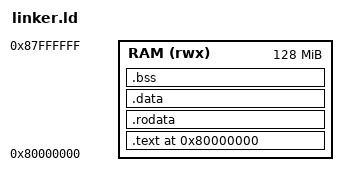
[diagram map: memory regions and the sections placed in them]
ENTRY(_start)

MEMORY
{
    RAM (rwx) : ORIGIN = 0x80000000, LENGTH = 128M
}

SECTIONS
{
    . = ORIGIN(RAM);

    .text :
    {
        *(.text.start)
        *(.text*)
    } > RAM

    .rodata :
    {
        *(.rodata*)
    } > RAM

    .data :
    {
        __data_start = .;
        *(.data*)
        __data_end = .;
    } > RAM

    .bss :
    {
        __bss_start = .;
        *(.bss*)
        *(COMMON)
        __bss_end = .;
    } > RAM

    . = ALIGN(16);

    _stack_top = ORIGIN(RAM) + LENGTH(RAM);
}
